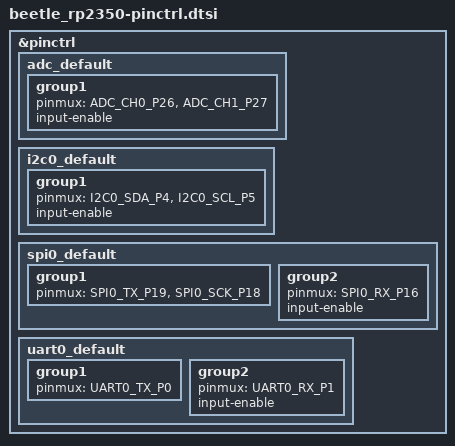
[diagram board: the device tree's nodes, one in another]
/*
 * Copyright (c) 2026 Jonas Berg
 *
 * SPDX-License-Identifier: Apache-2.0
 */

#include <zephyr/dt-bindings/pinctrl/rpi-pico-rp2350a-pinctrl.h>

&pinctrl {
	adc_default: adc_default {
		group1 {
			pinmux = <ADC_CH0_P26>, <ADC_CH1_P27>;
			input-enable;
		};
	};

	i2c0_default: i2c0_default {
		group1 {
			pinmux = <I2C0_SDA_P4>, <I2C0_SCL_P5>;
			input-enable;
		};
	};

	spi0_default: spi0_default {
		group1 {
			pinmux = <SPI0_TX_P19>, <SPI0_SCK_P18>;
		};

		group2 {
			pinmux = <SPI0_RX_P16>;
			input-enable;
		};
	};

	uart0_default: uart0_default {
		group1 {
			pinmux = <UART0_TX_P0>;
		};

		group2 {
			pinmux = <UART0_RX_P1>;
			input-enable;
		};
	};
};
